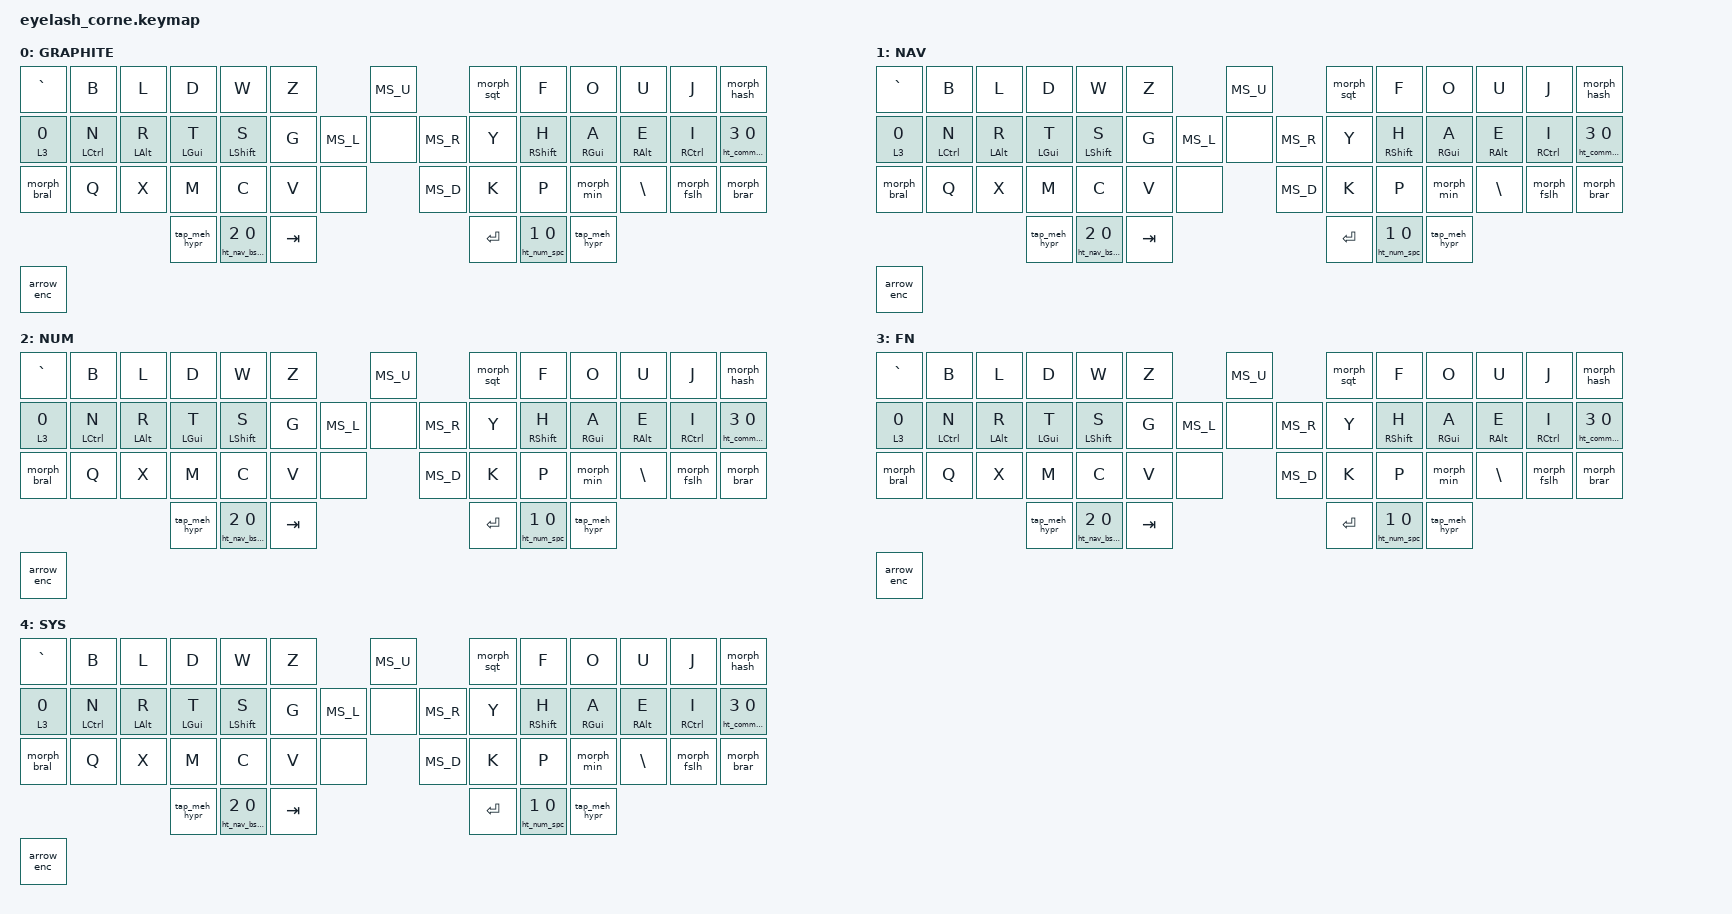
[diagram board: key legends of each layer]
#include <behaviors.dtsi>
#include <dt-bindings/zmk/bt.h>
#include <dt-bindings/zmk/keys.h>
#include <dt-bindings/zmk/outputs.h>
#include <dt-bindings/zmk/rgb.h>

#include <input/processors.dtsi>

#include <zephyr/dt-bindings/input/input-event-codes.h>

#include "zmk-helpers/helper.h"
#include "zmk-helpers/key-labels/eyelash42.h"

/*                42 KEY MATRIX with ENCODER and JOYSTICK / LAYOUT MAPPING
  ╭────────────────────────╮             ╭────╮      ╭─────────────────────────╮
  │  0   1   2   3   4   5 │         ╭───╯  6 ╰───╮  │   7   8   9  10  11  12 │
  │ 13  14  15  16  17  18 │ ╭────╮  │ 19  20  21 │  │  22  23  24  25  26  27 │
  │ 28  29  30  31  32  33 │ │ 34 │  ╰───╮ 35 ╭───╯  │  36  37  38  39  40  41 │
  ╰───────────╮ 42  43  44 │ ╰────╯      ╰────╯      │  45  46  47 ╭───────────╯
              ╰────────────╯                         ╰─────────────╯

  ╭──────────────────────────────╮              ╭─────╮      ╭──────────────────────────────╮
  │ LT5  LT4  LT3  LT2  LT1  LT0 │          ╭───╯ JS0 ╰───╮  │ RT0  RT1  RT2  RT3  RT4  RT5 │
  │ LM5  LM4  LM3  LM2  LM1  LM0 │ ╭─────╮  │ JS1 JS2 JS3 │  │ RM0  RM1  RM2  RM3  RM4  RM5 │
  │ LB5  LB4  LB3  LB2  LB1  LB0 │ │ LEC │  ╰───╮ JS4 ╭───╯  │ RB0  RB1  RB2  RB3  RB4  RB5 │
  ╰──────────────╮ LH2  LH1  LH0 │ ╰─────╯      ╰─────╯      │ RH0  RH1  RH2 ╭──────────────╯
                 ╰───────────────╯                           ╰───────────────╯

*/

#define KEYS_L      LT0 LT1 LT2 LT3 LT4 LT5 LM0 LM1 LM2 LM3 LM4 LM5 LB0 LB1 LB2 LB3 LB4 LB5
#define KEYS_R      RT0 RT1 RT2 RT3 RT4 RT5 RM0 RM1 RM2 RM3 RM4 RM5 RB0 RB1 RB2 RB3 RB4 RB5
#define THUMBS      LH2 LH1 LH0 RH0 RH1 RH2
#define ENC_PRESS   LEC
#define JOYSTICK    JS0 JS1 JS2 JS3 JS4

#define XXX &none
#define ___ &trans

#include "behavior_mouse.dtsi"
#include "behavior_encoder.dtsi"
#include "behavior_combo.dtsi"
#include "behavior_tap-dance.dtsi"
#include "behavior_mod-morph.dtsi"
// #include "adv_layers.dtsi"

/* Aliases */
#define T_SUPER     &tap_meh_hypr       // Tap CtlAltShift | DTap CtlAltMetaShift

#define M_COMMA     &morph_comma        // ,?
#define M_DOT       &morph_dot          // .!
#define M_SQT       &morph_sqt          // '_
#define M_MIN       &morph_min          // -"

#define M_DOT2      &morph_dot2         // ., NOTE keypad version TODO convert this into L_FN2
#define M_FSLH      &morph_fslh         // /%
#define M_EQL       &morph_eql          // =\ 
#define M_STAR      &morph_star         // *^
#define M_HASH      &morph_hash         // #$

#define M_BRAL      &morph_bral         // Tap ( | DTap [ | Tap+Shift { | DTap+Shift <
#define M_BRAR      &morph_brar         // Contra to above

// NOTE ignore the zero it's a workaround for MAKE_HT macro
#define SPC_NUM     &ht_num_spc   1 0   // Tap => Space | Tap+Shift => Insert | Hold => NUM Layer NOTE see behavior_mod-morph.dtsi for morph_spc definition 
#define BSPC_NAV    &ht_nav_bspc  2 0   // Tap => Bspc  | Tap+Shift => Delete | Hold => NAV Layer NOTE see behavior_mod-morph.dtsi for morph_bspc definition

#define L_FN        &ht_dot_fn    3 0   // Tap => . | Tap+Shift => ! | Hold => Fn Layer
#define R_FN        &ht_comma_fn  3 0   // Tap => , | Tap+Shift => ? | Hold => Fn Layer

#define T_BL        &tap_bluetooth      // Tap Delete BT Connection | DTap Delete ALL BT Connection

/* macOS Screenshot */
#define T_SCP       &tap_shot_part
#define T_SCF       &tap_shot_full
#define T_SCX       &kp LG(LS(5))       

/* macOS CopyPaste */
#define T_CC        &tap_copy_cut
#define T_PM        &tap_paste_move
#define T_ALL       &kp LG(A)

ZMK_LAYER(GRAPHITE,
    //  ╭─────────────┬─────────────┬─────────────┬─────────────┬─────────────┬─────────────╮                  ╭──────╮         ╭─────────────┬─────────────┬─────────────┬─────────────┬─────────────┬─────────────╮
        &kp GRAVE     &kp B         &kp L         &kp D         &kp W         &kp Z                             MS_U             M_SQT        &kp F         &kp O         &kp U         &kp J          M_HASH
    //  ├─────────────┼─────────────┼─────────────┼─────────────┼─────────────┼─────────────┤           ╭──────┼──────┼──────╮  ├─────────────┼─────────────┼─────────────┼─────────────┼─────────────┼─────────────┤ 
         L_FN         &hml LCTRL N  &hml LALT R   &hml LGUI T   &hml LSHFT S  &kp G                      MS_L   XXX  MS_R       &kp Y         &hmr RSHFT H  &hmr RGUI A   &hmr RALT E   &hmr RCTRL I   R_FN
    //  ├─────────────┼─────────────┼─────────────┼─────────────┼─────────────┼─────────────┤  ╭──────╮ ╰──────┼──────┼──────╯  ├─────────────┼─────────────┼─────────────┼─────────────┼─────────────┼─────────────┤
         M_BRAL       &kp Q         &kp X         &kp M         &kp C         &kp V             XXX             MS_D            &kp K         &kp P          M_MIN         &kp BSLH      M_FSLH        M_BRAR 
    //  ╰─────────────┴─────────────┴─────────────┼─────────────┼─────────────┼─────────────┤  ╰──────╯        ╰──────╯         ├─────────────┼─────────────┼─────────────┼─────────────┴─────────────┴─────────────╯
                                                  T_SUPER       BSPC_NAV      &kp TAB                                           &kp ENTER      SPC_NUM      T_SUPER
    //                                            ╰─────────────┴─────────────┴─────────────╯                                   ╰─────────────┴─────────────┴─────────────╯

    , &arrow_enc
)

ZMK_LAYER(NAV,
    //  ╭─────────────┬─────────────┬─────────────┬─────────────┬─────────────┬─────────────╮                  ╭──────╮         ╭─────────────┬─────────────┬─────────────┬─────────────┬─────────────┬─────────────╮
        &kp GRAVE     &kp B         &kp L         &kp D         &kp W         &kp Z                             MS_U             M_SQT        &kp F         &kp O         &kp U         &kp J          M_HASH
    //  ├─────────────┼─────────────┼─────────────┼─────────────┼─────────────┼─────────────┤           ╭──────┼──────┼──────╮  ├─────────────┼─────────────┼─────────────┼─────────────┼─────────────┼─────────────┤ 
         L_FN         &hml LCTRL N  &hml LALT R   &hml LGUI T   &hml LSHFT S  &kp G                      MS_L   XXX  MS_R       &kp Y         &hmr RSHFT H  &hmr RGUI A   &hmr RALT E   &hmr RCTRL I   R_FN
    //  ├─────────────┼─────────────┼─────────────┼─────────────┼─────────────┼─────────────┤  ╭──────╮ ╰──────┼──────┼──────╯  ├─────────────┼─────────────┼─────────────┼─────────────┼─────────────┼─────────────┤
         M_BRAL       &kp Q         &kp X         &kp M         &kp C         &kp V             XXX             MS_D            &kp K         &kp P          M_MIN         &kp BSLH      M_FSLH        M_BRAR 
    //  ╰─────────────┴─────────────┴─────────────┼─────────────┼─────────────┼─────────────┤  ╰──────╯        ╰──────╯         ├─────────────┼─────────────┼─────────────┼─────────────┴─────────────┴─────────────╯
                                                  T_SUPER       BSPC_NAV      &kp TAB                                           &kp ENTER      SPC_NUM      T_SUPER
    //                                            ╰─────────────┴─────────────┴─────────────╯                                   ╰─────────────┴─────────────┴─────────────╯

    , &arrow_enc
)

ZMK_LAYER(NUM,
    //  ╭─────────────┬─────────────┬─────────────┬─────────────┬─────────────┬─────────────╮                  ╭──────╮         ╭─────────────┬─────────────┬─────────────┬─────────────┬─────────────┬─────────────╮
        &kp GRAVE     &kp B         &kp L         &kp D         &kp W         &kp Z                             MS_U             M_SQT        &kp F         &kp O         &kp U         &kp J          M_HASH
    //  ├─────────────┼─────────────┼─────────────┼─────────────┼─────────────┼─────────────┤           ╭──────┼──────┼──────╮  ├─────────────┼─────────────┼─────────────┼─────────────┼─────────────┼─────────────┤ 
         L_FN         &hml LCTRL N  &hml LALT R   &hml LGUI T   &hml LSHFT S  &kp G                      MS_L   XXX  MS_R       &kp Y         &hmr RSHFT H  &hmr RGUI A   &hmr RALT E   &hmr RCTRL I   R_FN
    //  ├─────────────┼─────────────┼─────────────┼─────────────┼─────────────┼─────────────┤  ╭──────╮ ╰──────┼──────┼──────╯  ├─────────────┼─────────────┼─────────────┼─────────────┼─────────────┼─────────────┤
         M_BRAL       &kp Q         &kp X         &kp M         &kp C         &kp V             XXX             MS_D            &kp K         &kp P          M_MIN         &kp BSLH      M_FSLH        M_BRAR 
    //  ╰─────────────┴─────────────┴─────────────┼─────────────┼─────────────┼─────────────┤  ╰──────╯        ╰──────╯         ├─────────────┼─────────────┼─────────────┼─────────────┴─────────────┴─────────────╯
                                                  T_SUPER       BSPC_NAV      &kp TAB                                           &kp ENTER      SPC_NUM      T_SUPER
    //                                            ╰─────────────┴─────────────┴─────────────╯                                   ╰─────────────┴─────────────┴─────────────╯

    , &arrow_enc
)

ZMK_LAYER(FN,
    //  ╭─────────────┬─────────────┬─────────────┬─────────────┬─────────────┬─────────────╮                  ╭──────╮         ╭─────────────┬─────────────┬─────────────┬─────────────┬─────────────┬─────────────╮
        &kp GRAVE     &kp B         &kp L         &kp D         &kp W         &kp Z                             MS_U             M_SQT        &kp F         &kp O         &kp U         &kp J          M_HASH
    //  ├─────────────┼─────────────┼─────────────┼─────────────┼─────────────┼─────────────┤           ╭──────┼──────┼──────╮  ├─────────────┼─────────────┼─────────────┼─────────────┼─────────────┼─────────────┤ 
         L_FN         &hml LCTRL N  &hml LALT R   &hml LGUI T   &hml LSHFT S  &kp G                      MS_L   XXX  MS_R       &kp Y         &hmr RSHFT H  &hmr RGUI A   &hmr RALT E   &hmr RCTRL I   R_FN
    //  ├─────────────┼─────────────┼─────────────┼─────────────┼─────────────┼─────────────┤  ╭──────╮ ╰──────┼──────┼──────╯  ├─────────────┼─────────────┼─────────────┼─────────────┼─────────────┼─────────────┤
         M_BRAL       &kp Q         &kp X         &kp M         &kp C         &kp V             XXX             MS_D            &kp K         &kp P          M_MIN         &kp BSLH      M_FSLH        M_BRAR 
    //  ╰─────────────┴─────────────┴─────────────┼─────────────┼─────────────┼─────────────┤  ╰──────╯        ╰──────╯         ├─────────────┼─────────────┼─────────────┼─────────────┴─────────────┴─────────────╯
                                                  T_SUPER       BSPC_NAV      &kp TAB                                           &kp ENTER      SPC_NUM      T_SUPER
    //                                            ╰─────────────┴─────────────┴─────────────╯                                   ╰─────────────┴─────────────┴─────────────╯

    , &arrow_enc
)

ZMK_LAYER(SYS,
    //  ╭─────────────┬─────────────┬─────────────┬─────────────┬─────────────┬─────────────╮                  ╭──────╮         ╭─────────────┬─────────────┬─────────────┬─────────────┬─────────────┬─────────────╮
        &kp GRAVE     &kp B         &kp L         &kp D         &kp W         &kp Z                             MS_U             M_SQT        &kp F         &kp O         &kp U         &kp J          M_HASH
    //  ├─────────────┼─────────────┼─────────────┼─────────────┼─────────────┼─────────────┤           ╭──────┼──────┼──────╮  ├─────────────┼─────────────┼─────────────┼─────────────┼─────────────┼─────────────┤ 
         L_FN         &hml LCTRL N  &hml LALT R   &hml LGUI T   &hml LSHFT S  &kp G                      MS_L   XXX  MS_R       &kp Y         &hmr RSHFT H  &hmr RGUI A   &hmr RALT E   &hmr RCTRL I   R_FN
    //  ├─────────────┼─────────────┼─────────────┼─────────────┼─────────────┼─────────────┤  ╭──────╮ ╰──────┼──────┼──────╯  ├─────────────┼─────────────┼─────────────┼─────────────┼─────────────┼─────────────┤
         M_BRAL       &kp Q         &kp X         &kp M         &kp C         &kp V             XXX             MS_D            &kp K         &kp P          M_MIN         &kp BSLH      M_FSLH        M_BRAR 
    //  ╰─────────────┴─────────────┴─────────────┼─────────────┼─────────────┼─────────────┤  ╰──────╯        ╰──────╯         ├─────────────┼─────────────┼─────────────┼─────────────┴─────────────┴─────────────╯
                                                  T_SUPER       BSPC_NAV      &kp TAB                                           &kp ENTER      SPC_NUM      T_SUPER
    //                                            ╰─────────────┴─────────────┴─────────────╯                                   ╰─────────────┴─────────────┴─────────────╯

    , &arrow_enc
)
